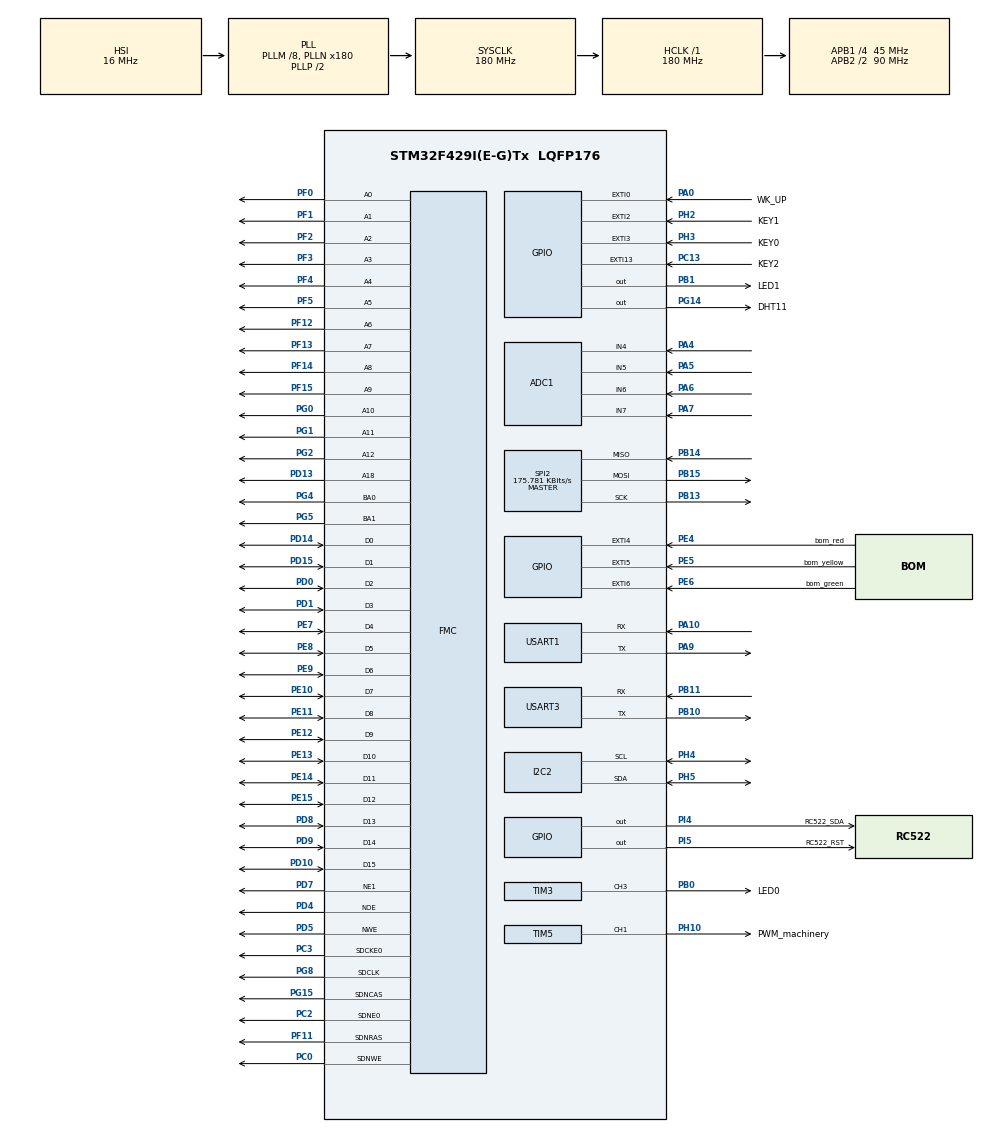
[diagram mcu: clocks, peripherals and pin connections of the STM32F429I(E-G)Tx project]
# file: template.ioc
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ADC1.Channel-4\#ChannelRegularConversion=ADC_CHANNEL_4
ADC1.Channel-5\#ChannelRegularConversion=ADC_CHANNEL_5
ADC1.Channel-6\#ChannelRegularConversion=ADC_CHANNEL_6
ADC1.Channel-7\#ChannelRegularConversion=ADC_CHANNEL_7
ADC1.ContinuousConvMode=ENABLE
ADC1.DMAContinuousRequests=ENABLE
ADC1.NbrOfConversion=4
ADC1.NbrOfConversionFlag=1
ADC1.Rank-4\#ChannelRegularConversion=1
ADC1.Rank-5\#ChannelRegularConversion=2
ADC1.Rank-6\#ChannelRegularConversion=3
ADC1.Rank-7\#ChannelRegularConversion=4
ADC1.SamplingTime-4\#ChannelRegularConversion=ADC_SAMPLETIME_15CYCLES
ADC1.SamplingTime-5\#ChannelRegularConversion=ADC_SAMPLETIME_15CYCLES
ADC1.SamplingTime-6\#ChannelRegularConversion=ADC_SAMPLETIME_15CYCLES
ADC1.SamplingTime-7\#ChannelRegularConversion=ADC_SAMPLETIME_15CYCLES
ADC1.ScanConvMode=ENABLE
ADC1.master=1
Dma.ADC1.1.Direction=DMA_PERIPH_TO_MEMORY
Dma.ADC1.1.FIFOMode=DMA_FIFOMODE_DISABLE
Dma.ADC1.1.Instance=DMA2_Stream0
Dma.ADC1.1.MemDataAlignment=DMA_MDATAALIGN_WORD
Dma.ADC1.1.MemInc=DMA_MINC_ENABLE
Dma.ADC1.1.Mode=DMA_CIRCULAR
Dma.ADC1.1.PeriphDataAlignment=DMA_PDATAALIGN_WORD
Dma.ADC1.1.PeriphInc=DMA_PINC_DISABLE
Dma.ADC1.1.Priority=DMA_PRIORITY_LOW
Dma.Request0=USART3_RX
Dma.Request1=ADC1
Dma.USART3_RX.0.Direction=DMA_PERIPH_TO_MEMORY
Dma.USART3_RX.0.FIFOMode=DMA_FIFOMODE_DISABLE
Dma.USART3_RX.0.Instance=DMA1_Stream1
Dma.USART3_RX.0.MemDataAlignment=DMA_MDATAALIGN_BYTE
Dma.USART3_RX.0.MemInc=DMA_MINC_ENABLE
Dma.USART3_RX.0.Mode=DMA_NORMAL
Dma.USART3_RX.0.PeriphDataAlignment=DMA_PDATAALIGN_BYTE
Dma.USART3_RX.0.PeriphInc=DMA_PINC_DISABLE
Dma.USART3_RX.0.Priority=DMA_PRIORITY_LOW
FMC.BusTurnAroundDuration1=1
FMC.CASLatency1=FMC_SDRAM_CAS_LATENCY_3
FMC.ColumnBitsNumber1=FMC_SDRAM_COLUMN_BITS_NUM_9
FMC.DataSetupTime1=46
FMC.ExitSelfRefreshDelay1=8
FMC.ExtendedBusTurnAroundDuration1=1
FMC.ExtendedDataSetupTime1=15
FMC.ExtendedMode1=FMC_EXTENDED_MODE_ENABLE
FMC.LoadToActiveDelay1=2
FMC.RCDDelay1=2
FMC.RPDelay1=2
FMC.ReadBurst1=FMC_SDRAM_RBURST_ENABLE
FMC.ReadPipeDelay1=FMC_SDRAM_RPIPE_DELAY_1
FMC.RowCycleDelay1=6
FMC.SDClockPeriod1=FMC_SDRAM_CLOCK_PERIOD_2
FMC.SelfRefreshTime1=6
FMC.WriteOperation1=FMC_WRITE_OPERATION_ENABLE
FMC.WriteRecoveryTime1=4
IWDG.Prescaler=IWDG_PRESCALER_64
Mcu.Family=STM32F4
Mcu.Name=STM32F429I(E-G)Tx
Mcu.Package=LQFP176
NVIC.DMA1_Stream1_IRQn=true\:0\:0\:false\:false\:true\:false\:true\:true
NVIC.DMA2_Stream0_IRQn=true\:0\:0\:false\:false\:true\:false\:true\:true
NVIC.EXTI0_IRQn=true\:1\:0\:true\:false\:true\:true\:true\:true
NVIC.EXTI15_10_IRQn=true\:1\:0\:true\:false\:true\:true\:true\:true
NVIC.EXTI2_IRQn=true\:1\:0\:true\:false\:true\:true\:true\:true
NVIC.EXTI3_IRQn=true\:1\:0\:true\:false\:true\:true\:true\:true
NVIC.EXTI4_IRQn=true\:1\:0\:true\:false\:true\:true\:true\:true
NVIC.EXTI9_5_IRQn=true\:3\:0\:true\:false\:true\:true\:true\:true
NVIC.PriorityGroup=NVIC_PRIORITYGROUP_4
NVIC.TIM1_UP_TIM10_IRQn=true\:4\:0\:true\:false\:true\:true\:true\:true
NVIC.TIM2_IRQn=true\:0\:0\:false\:false\:true\:true\:true\:true
NVIC.TIM5_IRQn=true\:4\:0\:true\:false\:true\:true\:true\:true
NVIC.USART3_IRQn=true\:0\:0\:false\:false\:true\:true\:true\:true
PA0/WKUP.GPIO_Label=WK_UP
PA0/WKUP.GPIO_PuPd=GPIO_PULLDOWN
PA0/WKUP.Signal=GPXTI0
PA10.Mode=Asynchronous
PA10.Signal=USART1_RX
PA13.Mode=Serial_Wire
PA13.Signal=SYS_JTMS-SWDIO
PA14.Mode=Serial_Wire
PA14.Signal=SYS_JTCK-SWCLK
PA3.GPIO_Label=input_machi
PA3.Signal=S_TIM2_CH4
PA4.Signal=ADCx_IN4
PA5.Signal=ADCx_IN5
PA6.Signal=ADCx_IN6
PA7.Signal=ADCx_IN7
PA9.Mode=Asynchronous
PA9.Signal=USART1_TX
PB0.GPIO_Label=LED0
PB0.Signal=S_TIM3_CH3
PB1.GPIO_Label=LED1
PB1.Signal=GPIO_Output
PB10.Mode=Asynchronous
PB10.Signal=USART3_TX
PB11.Mode=Asynchronous
PB11.Signal=USART3_RX
PB13.Mode=Full_Duplex_Master
PB13.Signal=SPI2_SCK
PB14.Mode=Full_Duplex_Master
PB14.Signal=SPI2_MISO
PB15.Mode=Full_Duplex_Master
PB15.Signal=SPI2_MOSI
PC0.Signal=FMC_SDNWE
PC13.GPIO_Label=KEY2
PC13.GPIO_PuPd=GPIO_PULLUP
PC13.Signal=GPXTI13
PC14/OSC32_IN.Mode=LSE-External-Oscillator
PC14/OSC32_IN.Signal=RCC_OSC32_IN
PC15/OSC32_OUT.Mode=LSE-External-Oscillator
PC15/OSC32_OUT.Signal=RCC_OSC32_OUT
PC2.Mode=SdramChipSelect1_1
PC2.Signal=FMC_SDNE0
PC3.Mode=SdramChipSelect1_1
PC3.Signal=FMC_SDCKE0
PD0.Signal=FMC_D2_DA2
PD1.Signal=FMC_D3_DA3
PD10.Signal=FMC_D15_DA15
PD13.Signal=FMC_A18
PD14.Signal=FMC_D0_DA0
PD15.Signal=FMC_D1_DA1
PD4.Signal=FMC_NOE
PD5.Signal=FMC_NWE
PD7.Mode=NorPsramChipSelect1_1
PD7.Signal=FMC_NE1
PD8.Signal=FMC_D13_DA13
PD9.Signal=FMC_D14_DA14
PE0.Signal=FMC_NBL0
PE1.Signal=FMC_NBL1
PE10.Signal=FMC_D7_DA7
PE11.Signal=FMC_D8_DA8
PE12.Signal=FMC_D9_DA9
PE13.Signal=FMC_D10_DA10
PE14.Signal=FMC_D11_DA11
PE15.Signal=FMC_D12_DA12
PE4.GPIO_Label=bom_red
PE4.GPIO_PuPd=GPIO_PULLDOWN
PE4.Signal=GPXTI4
PE5.GPIO_Label=bom_yellow
PE5.Signal=GPXTI5
PE6.GPIO_Label=bom_green
PE6.Signal=GPXTI6
PE7.Signal=FMC_D4_DA4
PE8.Signal=FMC_D5_DA5
PE9.Signal=FMC_D6_DA6
PF0.Signal=FMC_A0
PF1.Signal=FMC_A1
PF11.Signal=FMC_SDNRAS
PF12.Signal=FMC_A6
PF13.Signal=FMC_A7
PF14.Signal=FMC_A8
PF15.Signal=FMC_A9
PF2.Signal=FMC_A2
PF3.Signal=FMC_A3
PF4.Signal=FMC_A4
PF5.Signal=FMC_A5
PG0.Signal=FMC_A10
PG1.Signal=FMC_A11
PG14.GPIO_Label=DHT11
PG14.Signal=GPIO_Output
PG15.Signal=FMC_SDNCAS
PG2.Signal=FMC_A12
PG4.Signal=FMC_A14_BA0
PG5.Signal=FMC_A15_BA1
PG8.Signal=FMC_SDCLK
PH0/OSC_IN.Mode=HSE-External-Oscillator
PH0/OSC_IN.Signal=RCC_OSC_IN
PH1/OSC_OUT.Mode=HSE-External-Oscillator
PH1/OSC_OUT.Signal=RCC_OSC_OUT
PH10.GPIO_Label=PWM_machinery
PH10.Signal=S_TIM5_CH1
PH2.GPIO_Label=KEY1
PH2.GPIO_PuPd=GPIO_PULLUP
PH2.Signal=GPXTI2
PH3.GPIO_Label=KEY0
PH3.GPIO_PuPd=GPIO_PULLUP
PH3.Signal=GPXTI3
PH4.Mode=I2C
PH4.Signal=I2C2_SCL
PH5.Mode=I2C
PH5.Signal=I2C2_SDA
PI4.GPIO_Label=RC522_SDA
PI4.Signal=GPIO_Output
PI5.GPIO_Label=RC522_RST
PI5.Signal=GPIO_Output
ProjectManager.HeapSize=0xF00
ProjectManager.StackSize=0xF00
ProjectManager.TargetToolchain=MDK-ARM V5.32
RCC.48MHZClocksFreq_Value=90000000
RCC.AHBFreq_Value=180000000
RCC.APB1CLKDivider=RCC_HCLK_DIV4
RCC.APB1Freq_Value=45000000
RCC.APB1TimFreq_Value=90000000
RCC.APB2CLKDivider=RCC_HCLK_DIV2
RCC.APB2Freq_Value=90000000
RCC.APB2TimFreq_Value=180000000
RCC.CortexFreq_Value=180000000
RCC.HCLKFreq_Value=180000000
RCC.HSE_VALUE=25000000
RCC.HSI_VALUE=16000000
RCC.PLLM=8
RCC.PLLN=180
RCC.SYSCLKFreq_VALUE=180000000
RCC.SYSCLKSource=RCC_SYSCLKSOURCE_PLLCLK
RCC.VCOOutputFreq_Value=360000000
SH.ADCx_IN4.0=ADC1_IN4,IN4
SH.ADCx_IN5.0=ADC1_IN5,IN5
SH.ADCx_IN6.0=ADC1_IN6,IN6
SH.ADCx_IN7.0=ADC1_IN7,IN7
SH.FMC_A0.0=FMC_A0,13b-sda1
SH.FMC_A1.0=FMC_A1,13b-sda1
SH.FMC_A10.0=FMC_A10,13b-sda1
SH.FMC_A11.0=FMC_A11,13b-sda1
SH.FMC_A12.0=FMC_A12,13b-sda1
SH.FMC_A14_BA0.0=FMC_BA0,FourSdramBanks1
SH.FMC_A15_BA1.0=FMC_BA1,FourSdramBanks1
SH.FMC_A18.0=FMC_A18,A18_1
SH.FMC_A2.0=FMC_A2,13b-sda1
SH.FMC_A3.0=FMC_A3,13b-sda1
SH.FMC_A4.0=FMC_A4,13b-sda1
SH.FMC_A5.0=FMC_A5,13b-sda1
SH.FMC_A6.0=FMC_A6,13b-sda1
SH.FMC_A7.0=FMC_A7,13b-sda1
SH.FMC_A8.0=FMC_A8,13b-sda1
SH.FMC_A9.0=FMC_A9,13b-sda1
SH.FMC_D0_DA0.0=FMC_D0,16b-d1
SH.FMC_D0_DA0.1=FMC_D0,sd-16b-d1
SH.FMC_D10_DA10.0=FMC_D10,16b-d1
SH.FMC_D10_DA10.1=FMC_D10,sd-16b-d1
SH.FMC_D11_DA11.0=FMC_D11,16b-d1
SH.FMC_D11_DA11.1=FMC_D11,sd-16b-d1
SH.FMC_D12_DA12.0=FMC_D12,16b-d1
SH.FMC_D12_DA12.1=FMC_D12,sd-16b-d1
SH.FMC_D13_DA13.0=FMC_D13,16b-d1
SH.FMC_D13_DA13.1=FMC_D13,sd-16b-d1
SH.FMC_D14_DA14.0=FMC_D14,16b-d1
SH.FMC_D14_DA14.1=FMC_D14,sd-16b-d1
SH.FMC_D15_DA15.0=FMC_D15,16b-d1
SH.FMC_D15_DA15.1=FMC_D15,sd-16b-d1
SH.FMC_D1_DA1.0=FMC_D1,16b-d1
SH.FMC_D1_DA1.1=FMC_D1,sd-16b-d1
SH.FMC_D2_DA2.0=FMC_D2,16b-d1
SH.FMC_D2_DA2.1=FMC_D2,sd-16b-d1
SH.FMC_D3_DA3.0=FMC_D3,16b-d1
SH.FMC_D3_DA3.1=FMC_D3,sd-16b-d1
SH.FMC_D4_DA4.0=FMC_D4,16b-d1
SH.FMC_D4_DA4.1=FMC_D4,sd-16b-d1
SH.FMC_D5_DA5.0=FMC_D5,16b-d1
SH.FMC_D5_DA5.1=FMC_D5,sd-16b-d1
SH.FMC_D6_DA6.0=FMC_D6,16b-d1
SH.FMC_D6_DA6.1=FMC_D6,sd-16b-d1
SH.FMC_D7_DA7.0=FMC_D7,16b-d1
SH.FMC_D7_DA7.1=FMC_D7,sd-16b-d1
SH.FMC_D8_DA8.0=FMC_D8,16b-d1
SH.FMC_D8_DA8.1=FMC_D8,sd-16b-d1
SH.FMC_D9_DA9.0=FMC_D9,16b-d1
SH.FMC_D9_DA9.1=FMC_D9,sd-16b-d1
SH.FMC_NBL0.0=FMC_NBL0
SH.FMC_NBL1.0=FMC_NBL1
SH.FMC_NOE.0=FMC_NOE,Lcd1
SH.FMC_NWE.0=FMC_NWE,Lcd1
SH.FMC_SDCLK.0=FMC_SDCLK,13b-sda1
SH.FMC_SDNCAS.0=FMC_SDNCAS,13b-sda1
SH.FMC_SDNRAS.0=FMC_SDNRAS,13b-sda1
SH.FMC_SDNWE.0=FMC_SDNWE,13b-sda1
SH.S_TIM2_CH4.0=TIM2_CH4
SH.S_TIM3_CH3.0=TIM3_CH3,PWM Generation3 CH3
SH.S_TIM5_CH1.0=TIM5_CH1,PWM Generation1 CH1
SPI2.BaudRatePrescaler=SPI_BAUDRATEPRESCALER_256
SPI2.CalculateBaudRate=175.781 KBits/s
SPI2.Direction=SPI_DIRECTION_2LINES
SPI2.Mode=SPI_MODE_MASTER
SPI2.VirtualType=VM_MASTER
TIM1.Period=10000-1
TIM1.Prescaler=18000-1
TIM2.AutoReloadPreload=TIM_AUTORELOAD_PRELOAD_ENABLE
TIM2.Period=1000
TIM2.Prescaler=18000-1
TIM3.AutoReloadPreload=TIM_AUTORELOAD_PRELOAD_ENABLE
TIM3.Channel-PWM\ Generation3\ CH3=TIM_CHANNEL_3
TIM3.Period=500
TIM3.Prescaler=180-1
TIM5.AutoReloadPreload=TIM_AUTORELOAD_PRELOAD_ENABLE
TIM5.Channel-PWM\ Generation1\ CH1=TIM_CHANNEL_1
TIM5.Period=500-1
TIM5.Prescaler=180-1
TIM5.Pulse-PWM\ Generation1\ CH1=400
USART1.VirtualMode=VM_ASYNC
USART3.VirtualMode=VM_ASYNC
VP_IWDG_VS_IWDG.Mode=IWDG_Activate
VP_TIM1_VS_ClockSourceINT.Mode=Internal
VP_TIM2_VS_ClockSourceINT.Mode=Internal
VP_TIM3_VS_ClockSourceINT.Mode=Internal
VP_TIM5_VS_ClockSourceINT.Mode=Internal
board=custom

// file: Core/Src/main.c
/* USER CODE BEGIN Header */
/**
  ******************************************************************************
  * @file           : main.c
  * @brief          : Main program body
  ******************************************************************************
  * @attention
  *
  * Copyright (c) 2023 STMicroelectronics.
  * All rights reserved.
  *
  * This software is licensed under terms that can be found in the LICENSE file
  * in the root directory of this software component.
  * If no LICENSE file comes with this software, it is provided AS-IS.
  *
  ******************************************************************************
  */
/* USER CODE END Header */
#include "main.h"
#include "adc.h"
#include "dma.h"
#include "i2c.h"
#include "iwdg.h"
#include "spi.h"
#include "tim.h"
#include "usart.h"
#include "gpio.h"
#include "fmc.h"

/* USER CODE BEGIN Includes */
#include "wifi.h"
#include "onenet.h"
#include "lcd.h"
#include "24c02.h"
#include "sdram.h"
#include "key.h"
#include "malloc.h"
#include "PCF8574.h"
#include "dht11.h"
#include "rc522.h"
#include "key_exit.h"

/* USER CODE END Includes */

/* USER CODE BEGIN PTD */

#define AT_24_DATA_MAX 100
struct AT24CDATA
{
    uint8_t 	arr[AT_24_DATA_MAX];
    uint16_t 	len;
    uint16_t	addr;
};

uint16_t ID_Cart = 0;
uint16_t Device_ID = 2002;

uint8_t mode_flag = 0;     // 0 复位   1 自动模式  2 手动模式

/* USER CODE END PTD */

/* USER CODE BEGIN PV */
void sensor_read_data(void);
/* USER CODE END PV */

void SystemClock_Config(void);

/* USER CODE BEGIN 0 */
uint8_t net_connect = 0;            // 网咯是否连接的标志位
uint8_t connet_send_flag = 0;
uint32_t adc_value[40];              //adc数据缓冲区

extern uint8_t  TIM2CH4_CAPTURE_STA;	//输入捕获状态
extern uint32_t	TIM2CH4_CAPTURE_VAL;	//输入捕获值(TIM2/TIM5是32位)

uint32_t value1 = 0, value2 = 0, value3 = 0, value4 = 0;
uint8_t i = 0;                       //for循环用到的变量而已

double temperature = 0;             //温度
double humidity = 0;                //湿度
uint32_t Lighting = 0, Turbidity = 0, Gas = 0; //光照，浊度，烟雾的数据
char buf1[128];
//char buf2[40];
uint8_t at_data_arr[256];
uint16_t at24_addr = 0;
float voltage = 0;  // 电压

uint8_t cmd_flag = 0;    // 命令打印标志位

//void sensor_read_data(void);

extern uint8_t net_connect;
struct AT24CDATA at_data_struct = {0};    // 掉电的结构体

char json_arr[256];

extern uint8_t Data[5];

uint16_t pwm_mach = PWM_MAC_PWM;

uint8_t capture_state;
uint16_t capture_val;

uint16_t TH_Temp = 33;   //
uint16_t TH_Hum = 60;
uint16_t TH_Gas = 80;
uint8_t TH_light = 30;
uint8_t beep_flag = 0;   // 1 温度过高  2

void beep_on(uint8_t m)
{
	if(m){
		PCF8574_WriteBit(BEEP_IO,1);
	}
	else
		PCF8574_WriteBit(BEEP_IO,0);
}

//	TIM3->CCR3 = 0;    // 0 亮
void light_mode(uint8_t m)
{
	led_num = m;
	if(m==0){
		TIM3->CCR3 = 499;
	}
	if(m==1){
		TIM3->CCR3 = 400;
	}
	if(m==2)
	{
		TIM3->CCR3 = 0;
	}
	printf("led 切换为模式 %d\r\n",m);
}

void fan_mode(uint8_t m)
{
	fan_num = m;
	if(m==0){
		TIM5->CCR1 = 499;
	}
	if(m==1){
		TIM5->CCR1 = 400;
	}
	if(m==2)
	{
		TIM5->CCR1 = 0;
	}
	printf("风扇切换为模式 %d\r\n",m);

}

// 智能家居判断函数
void zhineng(void)
{
	// 自动模式
	if(mode_flag==1)
	{
		if(Lighting>TH_light)
		{
			light_mode(0);

		}
		else{
			light_mode(1);
		}
		if(Gas>TH_Gas)
		{
			beep_flag = 3;
//			OneNet_Send_One_Int_Data("Beep",3);
		}

		if(temperature>TH_Temp)
		{
			beep_flag = 1;
//			OneNet_Send_One_Int_Data("Beep",1);
		}

		if(humidity>TH_Hum)
		{
			beep_flag = 2;
//			OneNet_Send_One_Int_Data("Beep",2);
		}
		if(Gas<TH_Gas||temperature<TH_Temp||humidity<TH_Hum)
		{
			beep_flag = 0;
//			OneNet_Send_One_Int_Data("Beep",0);
		}

	}

}

char show_buff[124];
void lcd_show_water(void)
{
	LCD_Clear(WHITE);
	// 显示时间
	memset(show_buff,0,sizeof(show_buff));
	sprintf(show_buff,"time:%d-%d-%d-%d-%d-%d",year_time,moon_time,sun_time,hour_time,minute_time,second_time);
    LCD_ShowString(10, 40, 460, 32, 32, (uint8_t *)show_buff);

		// 显示设备号
	memset(show_buff,0,sizeof(show_buff));
	sprintf(show_buff,"device:%d",Device_ID);
	LCD_ShowString(10,80,560,32,32,(uint8_t *)show_buff);

		// 显示阈值水温
	memset(show_buff,0,sizeof(show_buff));
	sprintf(show_buff,"TH_tem:%d  TH_Hum:%d",TH_Temp,TH_Hum);
	LCD_ShowString(10,120,560,32,32,(uint8_t *)show_buff);

	// 显示水温
	memset(show_buff,0,sizeof(show_buff));
	sprintf(show_buff,"temp:%.2f  Hum:%.2f",temperature,humidity);
	LCD_ShowString(10,160,560,32,32,(uint8_t *)show_buff);

		// 显示gas
	memset(show_buff,0,sizeof(show_buff));
	sprintf(show_buff,"Gas:%d   TH_Gas:%d ",Gas,TH_Gas);
	LCD_ShowString(10,200,560,32,32,(uint8_t *)show_buff);

		// 显示light
	memset(show_buff,0,sizeof(show_buff));
	sprintf(show_buff,"light:%d   TH_light:%d ",Lighting,TH_light);
	LCD_ShowString(10,240,560,32,32,(uint8_t *)show_buff);

	memset(show_buff,0,sizeof(show_buff));
	if(beep_flag==1){
			sprintf(show_buff,"     temp over ");
	}
	else if(beep_flag==2){
		sprintf(show_buff,"     humi over ");
	}
	else if(beep_flag==3){
		sprintf(show_buff,"     Gas over ");
	}
	else if(beep_flag ==4 )
	{
		sprintf(show_buff,"     people over ");
	}
	else if(led_num>0)
	{
		sprintf(show_buff,"     light over ");
	}
	LCD_ShowString(10,280,560,32,32,(uint8_t *)show_buff);

}

/* USER CODE END 0 */

int main(void)
{
  /* USER CODE BEGIN 1 */
    uint16_t timeCount = 0;
    //	uint16_t time_wwdg = 0;
    unsigned char *dataPtr = NULL;
    uint8_t net_cone_num = 0;
  /* USER CODE END 1 */

  /* MCU Configuration--------------------------------------------------------*/

  /* Reset of all peripherals, Initializes the Flash interface and the Systick. */
  HAL_Init();

  /* Configure the system clock */
  SystemClock_Config();

  /* Initialize all configured peripherals */
  MX_GPIO_Init();
  MX_DMA_Init();
  MX_USART1_UART_Init();
  MX_USART3_UART_Init();
  MX_FMC_Init();
  MX_ADC1_Init();
  MX_I2C2_Init();
  MX_TIM1_Init();
  MX_SPI2_Init();
  MX_IWDG_Init();
  MX_TIM5_Init();
  MX_TIM3_Init();
  MX_TIM2_Init();
  /* USER CODE BEGIN 2 */
	HAL_TIM_PWM_Start(&htim5,TIM_CHANNEL_1);
	HAL_TIM_PWM_Start(&htim3,TIM_CHANNEL_3);   // lde灯
	HAL_TIM_Base_Start_IT(&htim1);

//	printf("init\r\n");
    delay_init(180);

//	while(1)
//	{
//		HAL_Delay(1000);
//		fan_mode(0);
//		HAL_Delay(1000);
//		fan_mode(1);
//	}

    LCD_Init();
    while(AT24C02_Check()) {}
    while(pcf8574_Check()) {}

//    RC522_Init();
//    printf("等待管理员的卡\r\n");
//	LCD_ShowString(100,100,240,32,32,"wait RFID...");
//
//	while(ReaderCard() == 0)

    DHT11_Init();

    SDRAM_Init();

    my_mem_init(SRAMIN);		    //初始化内部内存池
    my_mem_init(SRAMEX);		    //初始化外部内存池
    my_mem_init(SRAMCCM);		    //初始化CCM内存池

    KEY_Init();
//	HAL_TIM_IC_Start_IT(&htim5,TIM_CHANNEL_2);
//	__HAL_TIM_ENABLE_IT(&htim5, TIM_CHANNEL_2);

//    LCD_ShowString(10, 40, 240, 32, 32, "Apollo STM32F4/F7");
//    LCD_ShowString(10, 80, 240, 24, 24, "TFTLCD TEST");
//    LCD_ShowString(10, 110, 240, 16, 16, "ATOM@ALIENTEK");
//    // 		LCD_ShowString(10,130,240,16,16,lcd_id);		//显示LCD ID
//    LCD_ShowString(10, 150, 240, 12, 12, "2016/1/6");

  /* USER CODE END 2 */

  /* Infinite loop */
  /* USER CODE BEGIN WHILE */
	mode_flag = 1;
    while (1)
    {
        //	  printf("sdjj\r\n");
        if(net_connect == 1)   // 连接成功
        {

			zhineng();
            if(timeCount % 10 == 0)
            {
                // 发送数据
                sensor_read_data();

				if(time_flag!=0)
				{
					// 请求时间同步
					OneNet_Send_Device_ID_Data();
				}

            }
            ++timeCount;
            if(timeCount >= 20)		//时间间隔5s 发送
            {

                //				OneNet_SendData_State("EEROR");

                HAL_Delay(100);
                printf( "开始发送数据\r\n");//通过串口1发送提示信息（要开始发送数据了）
                OneNet_SendData();//发送数据给onenet
                printf("发送数据结束\n");
                //				while(OneNet_DevLink())			//接入OneNET
                timeCount = 0;
                ESP8266_Clear();
            }
            //            ESP8266_GetIPD(0);//获取平台返回的数据
            dataPtr = ESP8266_GetIPD(0);//获取平台返回的数据
            if(dataPtr != NULL)//如果返回数据不为空
                OneNet_RevPro(dataPtr);//平台返回数据检测

            HAL_Delay(40);
        }

        else if(net_connect == 2 || net_connect == 3)
        {
            ++timeCount;

            //==============================================================    断网数据采集 ===================================
            if(timeCount % 4 == 0)
            {

                //发送数据
                sensor_read_data();
                OneNet_FillBuf(json_arr, 1);
                // 掉电保存

                AT24C02_write(at_data_struct.addr, (uint8_t *)json_arr, strlen(json_arr));
                at_data_struct.arr[at_data_struct.len++] = strlen(json_arr);
                memset(at_data_arr, 0, sizeof(at_data_arr));
                AT24C02_read(at_data_struct.addr, at_data_arr, strlen(json_arr));
                printf("断网保存成功 = %s\r\n", at_data_arr);
                at_data_struct.addr += strlen(json_arr);
                timeCount = 0;
                //				HAL_IWDG_Refresh(&hiwdg);               // 喂狗
            }

            // ==========================================net_connect=2 尝试重连==================================
            if(net_connect == 2)
            {
                if(ESP8266_SendCmd("AT\r\n", "OK") == 0)
                {
                    if(ESP8266_SendCmd("AT+RST\r\n", "ready") == 0)
                    {
                        //					HAL_Delay(2000);
                        //					Usart_SendString(USART2, (unsigned char *)"AT+RST\r\n", strlen((const char *)"AT+RST\r\n"));
                        HAL_Delay(200);
                        if(ESP8266_SendCmd("AT+CWMODE=1\r\n", "OK") == 0)
                        {
                            if(ESP8266_SendCmd("AT+CWDHCP=1,1\r\n", "OK") == 0)
                            {
                                //								HAL_Delay(200);
                                while(ESP8266_SendCmd(ESP8266_WIFI_INFO, "GOT IP")) {}
                                while(ESP8266_SendCmd(ESP8266_WIFI_INFO, "GOT IP"))
                                {
                                    net_cone_num++;
                                    if(net_cone_num > 20)
                                    {

                                        break;
                                    }
                                    //									}
                                }
                                if(net_cone_num < 20)
                                {
                                    net_connect = 3;
                                    printf("net_connet = %d\r\n", net_connect);
                                }
                                net_cone_num = 0;
                            }
                        }
                    }
                }
            }
            if(net_connect == 3)
            {
                net_cone_num = 5;
                printf("进入net_connet = %d\r\n", net_connect);
                while(ESP8266_SendCmd(ESP8266_ONENET_INFO, "CONNECT") == 0)
                {
                    while(OneNet_DevLink())			//接入OneNET
                    {
                        if(net_connect == 2)
                            break;
                    }
                    if(net_connect != 2)
                    {
                        HAL_Delay(1000);
                        printf("接入onenet成功");
                        net_connect  = 1;
                        at24_addr = 0;

                        for(i = 0; i < at_data_struct.len; i++)
                        {
                            memset(at_data_arr, 0, sizeof(at_data_arr));
                            AT24C02_read(at24_addr, at_data_arr, at_data_struct.arr[i]);
                            if(OneNet_SendData_Buff((char *)at_data_arr))
                            {
                                connet_send_flag = 1;
                            }
                            at24_addr += at_data_struct.arr[i];
                            printf("重发数据 %d = %s\r\n", i, at_data_arr);
                        }
                        connet_send_flag = 0;
                        ESP8266_Clear();									//清空缓存
                        break;
                    }
                    //					while()

                }

            }
        }

    /* USER CODE END WHILE */

    /* USER CODE BEGIN 3 */

        else
        {
            printf("开始连接服务器\r\n");
            ESP8266_Init();					//初始化ESP8266

            printf("8266初始化成功\n");

            while(OneNet_DevLink())			//接入OneNET

			HAL_Delay(200);
            net_connect = 1;
            HAL_ADC_Start_DMA(&hadc1, (uint32_t *)adc_value, 40);

            printf("接入onenet成功");
        }
    }
  /* USER CODE END 3 */
}

void SystemClock_Config(void)
{
  RCC_OscInitTypeDef RCC_OscInitStruct = {0};
  RCC_ClkInitTypeDef RCC_ClkInitStruct = {0};

  /** Configure the main internal regulator output voltage
  */
  __HAL_RCC_PWR_CLK_ENABLE();
  __HAL_PWR_VOLTAGESCALING_CONFIG(PWR_REGULATOR_VOLTAGE_SCALE1);

  /** Initializes the RCC Oscillators according to the specified parameters
  * in the RCC_OscInitTypeDef structure.
  */
  RCC_OscInitStruct.OscillatorType = RCC_OSCILLATORTYPE_HSI|RCC_OSCILLATORTYPE_LSI;
  RCC_OscInitStruct.HSIState = RCC_HSI_ON;
  RCC_OscInitStruct.HSICalibrationValue = RCC_HSICALIBRATION_DEFAULT;
  RCC_OscInitStruct.LSIState = RCC_LSI_ON;
  RCC_OscInitStruct.PLL.PLLState = RCC_PLL_ON;
  RCC_OscInitStruct.PLL.PLLSource = RCC_PLLSOURCE_HSI;
  RCC_OscInitStruct.PLL.PLLM = 8;
  RCC_OscInitStruct.PLL.PLLN = 180;
  RCC_OscInitStruct.PLL.PLLP = RCC_PLLP_DIV2;
  RCC_OscInitStruct.PLL.PLLQ = 4;
  if (HAL_RCC_OscConfig(&RCC_OscInitStruct) != HAL_OK)
  {
    Error_Handler();
  }

  /** Activate the Over-Drive mode
  */
  if (HAL_PWREx_EnableOverDrive() != HAL_OK)
  {
    Error_Handler();
  }

  /** Initializes the CPU, AHB and APB buses clocks
  */
  RCC_ClkInitStruct.ClockType = RCC_CLOCKTYPE_HCLK|RCC_CLOCKTYPE_SYSCLK
                              |RCC_CLOCKTYPE_PCLK1|RCC_CLOCKTYPE_PCLK2;
  RCC_ClkInitStruct.SYSCLKSource = RCC_SYSCLKSOURCE_PLLCLK;
  RCC_ClkInitStruct.AHBCLKDivider = RCC_SYSCLK_DIV1;
  RCC_ClkInitStruct.APB1CLKDivider = RCC_HCLK_DIV4;
  RCC_ClkInitStruct.APB2CLKDivider = RCC_HCLK_DIV2;

  if (HAL_RCC_ClockConfig(&RCC_ClkInitStruct, FLASH_LATENCY_5) != HAL_OK)
  {
    Error_Handler();
  }
}

/* USER CODE BEGIN 4 */
void sensor_read_data(void)
{
    //===============================================dht11读取======================================================
    DHT11_Read_Data(&humidity, &temperature);
    printf("temperature = %.2f		humidity = %.2f\r\n", temperature, humidity);
    //================================================================================================================

    //===============================================adc通道读取======================================================
    for(i = 0, value1 = 0, value2 = 0, value3 = 0, value4 = 0; i < 40;)
    {
        value1 += adc_value[i++];
        value2 += adc_value[i++];
        value3 += adc_value[i++];
        value4 += adc_value[i++];
    }
    printf("value1 = %d    value2 = %d     value3 = %d    value4 = %d\r\n", value1, value2, value3, value4);
    // PA4
    Lighting = (4096 - value1 / 10) * 100 / 4096; //亮度
    printf("检测光亮值为：%d%%\r\n", Lighting);

    voltage = (float)value2 / 10 * (3.3 / 4096);
    printf("检测电压值为1：%.3fV\r\n", voltage);

    Turbidity = (value3 / 10) * 100 / 4096; //浊度
    printf("检测浊度值为：%d\r\n", Turbidity);
    Gas = (4096 - value4 / 10) * 100 / 4096; //烟雾
    printf("检测烟雾值为：%d%%\r\n", Gas);

    HAL_Delay(2000);
    value1 = value2 = value3 = value4 = 0;
    //====================================================================================================================
}
/* USER CODE END 4 */

void Error_Handler(void)
{
    __disable_irq();
    while (1)
    {
    }
}
